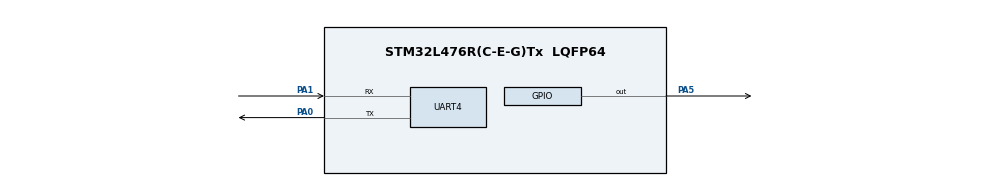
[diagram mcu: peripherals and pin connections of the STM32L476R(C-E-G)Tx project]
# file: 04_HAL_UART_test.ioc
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Mcu.Family=STM32L4
Mcu.Name=STM32L476R(C-E-G)Tx
Mcu.Package=LQFP64
NVIC.PriorityGroup=NVIC_PRIORITYGROUP_4
PA0.Mode=Asynchronous
PA0.Signal=UART4_TX
PA1.Mode=Asynchronous
PA1.Signal=UART4_RX
PA5.Signal=GPIO_Output
ProjectManager.HeapSize=0x200
ProjectManager.StackSize=0x400
ProjectManager.TargetToolchain=STM32CubeIDE
RCC.HSE_VALUE=8000000
RCC.HSI_VALUE=16000000
RCC.LSE_VALUE=32768
RCC.MSI_VALUE=4000000
RCC.VCOOutputFreq_Value=32000000
board=custom

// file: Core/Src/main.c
/* USER CODE BEGIN Header */
/**
  ******************************************************************************
  * @file           : main.c
  * @brief          : Main program body
  ******************************************************************************
  * @attention
  *
  * Copyright (c) 2026 STMicroelectronics.
  * All rights reserved.
  *
  * This software is licensed under terms that can be found in the LICENSE file
  * in the root directory of this software component.
  * If no LICENSE file comes with this software, it is provided AS-IS.
  *
  ******************************************************************************
  */
/* USER CODE END Header */
#include "main.h"

/* USER CODE BEGIN PM */
#define Send_Data 1
/* USER CODE END PM */

UART_HandleTypeDef huart4;

void SystemClock_Config(void);
static void MX_GPIO_Init(void);
static void MX_UART4_Init(void);

/* USER CODE BEGIN 0 */
uint8_t TxBuf[4] = {0x11,0x22,0x33,0x44};

uint8_t RxBuf;

int __io_putchar(int ch)
{
    HAL_UART_Transmit(&huart4, (uint8_t *)&ch, 1, HAL_MAX_DELAY);
    return ch;
}

int __io_getchar(void)
{
    uint8_t ch = 0;
    HAL_UART_Receive(&huart4, &ch, 1, HAL_MAX_DELAY);
    return ch;
}
/* USER CODE END 0 */

int main(void)
{

  /* MCU Configuration--------------------------------------------------------*/

  /* Reset of all peripherals, Initializes the Flash interface and the Systick. */
  HAL_Init();

  /* Configure the system clock */
  SystemClock_Config();

  /* Initialize all configured peripherals */
  MX_GPIO_Init();
  MX_UART4_Init();

  /* Infinite loop */
  /* USER CODE BEGIN WHILE */
  while (1)
  {
//	  if(HAL_UART_Receive(&huart4, RxBuf, 1, 10000) == HAL_OK)
//	  {
//		  if(RxBuf == Send_Data)
//		  HAL_UART_Transmit(&huart4, TxBuf, 4, 10000);
//	  }

	        RxBuf = getchar();   // receive from YAT

	        if(RxBuf == Send_Data)
	        {
	        	printf("hello bitsilica\n", RxBuf); // send back to YAT
	        }

	/* USER CODE END WHILE */

  }
}

void SystemClock_Config(void)
{
  RCC_OscInitTypeDef RCC_OscInitStruct = {0};
  RCC_ClkInitTypeDef RCC_ClkInitStruct = {0};

  /** Configure the main internal regulator output voltage
  */
  if (HAL_PWREx_ControlVoltageScaling(PWR_REGULATOR_VOLTAGE_SCALE1) != HAL_OK)
  {
    Error_Handler();
  }

  /** Initializes the RCC Oscillators according to the specified parameters
  * in the RCC_OscInitTypeDef structure.
  */
  RCC_OscInitStruct.OscillatorType = RCC_OSCILLATORTYPE_MSI;
  RCC_OscInitStruct.MSIState = RCC_MSI_ON;
  RCC_OscInitStruct.MSICalibrationValue = 0;
  RCC_OscInitStruct.MSIClockRange = RCC_MSIRANGE_6;
  RCC_OscInitStruct.PLL.PLLState = RCC_PLL_NONE;
  if (HAL_RCC_OscConfig(&RCC_OscInitStruct) != HAL_OK)
  {
    Error_Handler();
  }

  /** Initializes the CPU, AHB and APB buses clocks
  */
  RCC_ClkInitStruct.ClockType = RCC_CLOCKTYPE_HCLK|RCC_CLOCKTYPE_SYSCLK
                              |RCC_CLOCKTYPE_PCLK1|RCC_CLOCKTYPE_PCLK2;
  RCC_ClkInitStruct.SYSCLKSource = RCC_SYSCLKSOURCE_MSI;
  RCC_ClkInitStruct.AHBCLKDivider = RCC_SYSCLK_DIV1;
  RCC_ClkInitStruct.APB1CLKDivider = RCC_HCLK_DIV1;
  RCC_ClkInitStruct.APB2CLKDivider = RCC_HCLK_DIV1;

  if (HAL_RCC_ClockConfig(&RCC_ClkInitStruct, FLASH_LATENCY_0) != HAL_OK)
  {
    Error_Handler();
  }
}

static void MX_UART4_Init(void)
{

  huart4.Instance = UART4;
  huart4.Init.BaudRate = 115200;
  huart4.Init.WordLength = UART_WORDLENGTH_8B;
  huart4.Init.StopBits = UART_STOPBITS_1;
  huart4.Init.Parity = UART_PARITY_NONE;
  huart4.Init.Mode = UART_MODE_TX_RX;
  huart4.Init.HwFlowCtl = UART_HWCONTROL_NONE;
  huart4.Init.OverSampling = UART_OVERSAMPLING_16;
  huart4.Init.OneBitSampling = UART_ONE_BIT_SAMPLE_DISABLE;
  huart4.AdvancedInit.AdvFeatureInit = UART_ADVFEATURE_NO_INIT;
  if (HAL_UART_Init(&huart4) != HAL_OK)
  {
    Error_Handler();
  }

}

static void MX_GPIO_Init(void)
{
  GPIO_InitTypeDef GPIO_InitStruct = {0};

  /* GPIO Ports Clock Enable */
  __HAL_RCC_GPIOA_CLK_ENABLE();

  /*Configure GPIO pin Output Level */
  HAL_GPIO_WritePin(GPIOA, GPIO_PIN_5, GPIO_PIN_RESET);

  /*Configure GPIO pin : PA5 */
  GPIO_InitStruct.Pin = GPIO_PIN_5;
  GPIO_InitStruct.Mode = GPIO_MODE_OUTPUT_PP;
  GPIO_InitStruct.Pull = GPIO_NOPULL;
  GPIO_InitStruct.Speed = GPIO_SPEED_FREQ_LOW;
  HAL_GPIO_Init(GPIOA, &GPIO_InitStruct);

}

void Error_Handler(void)
{
  __disable_irq();
  while (1)
  {
  }
}
